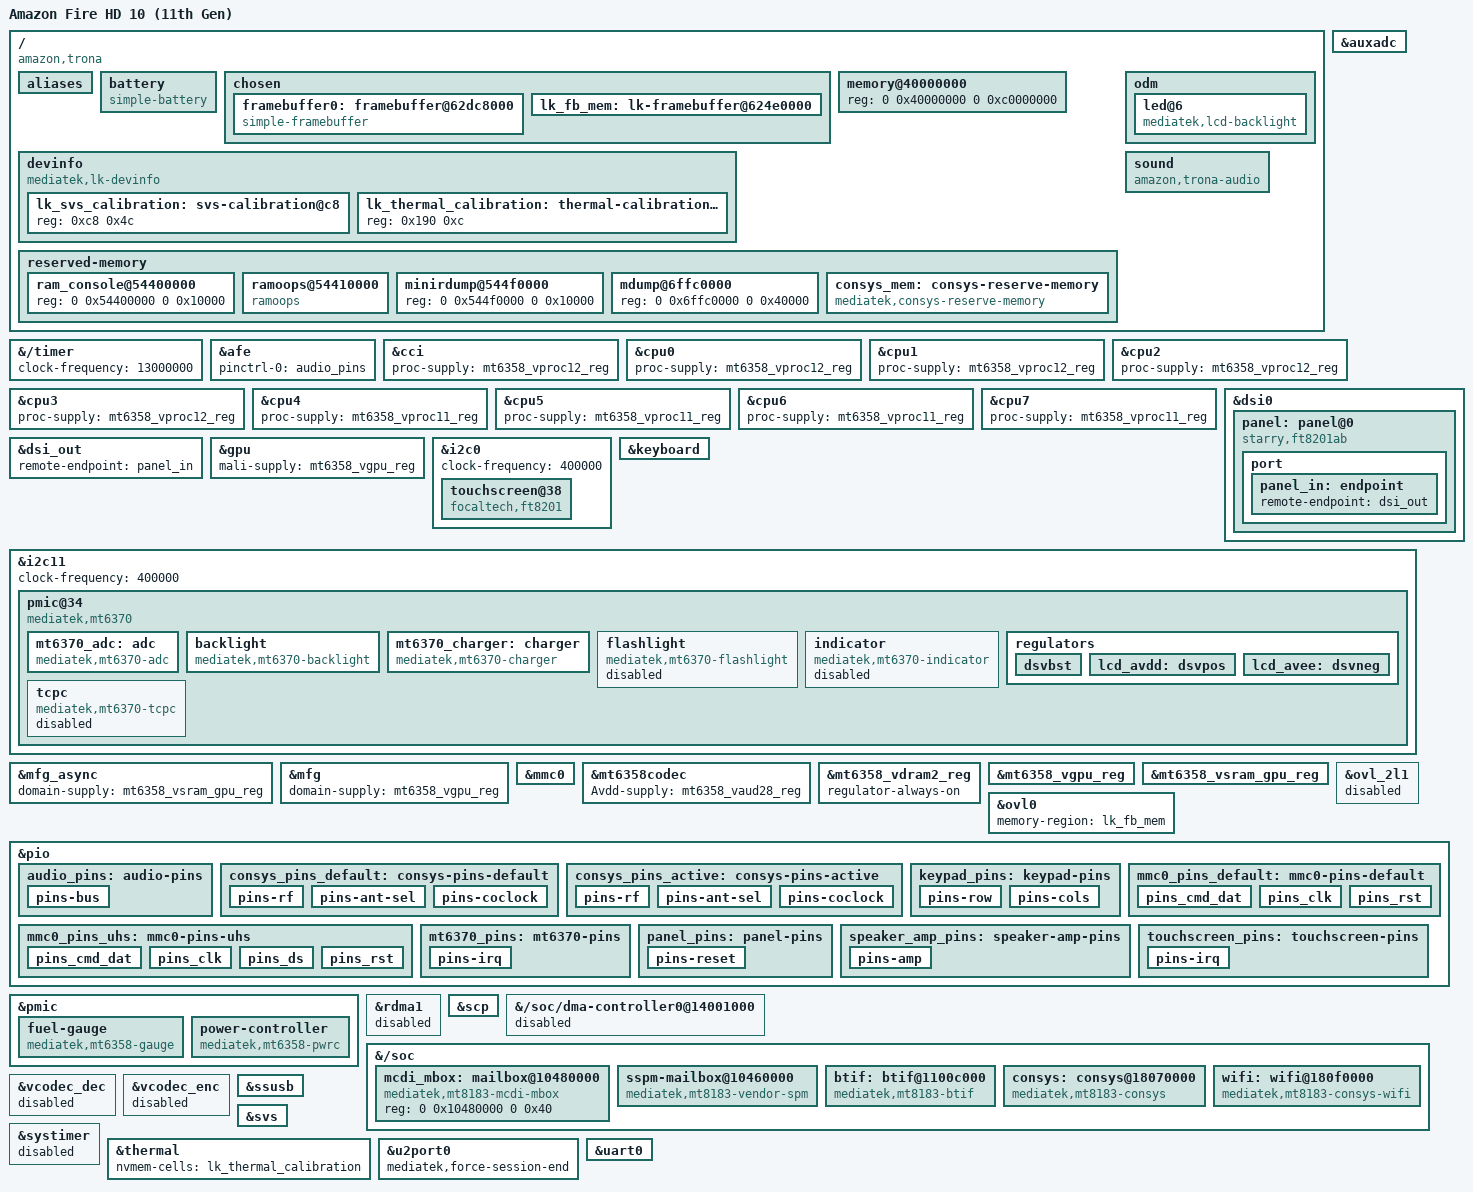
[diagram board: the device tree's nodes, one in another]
// SPDX-License-Identifier: (GPL-2.0 OR MIT)
/*
 * Amazon Fire HD 10 (11th Gen, 2021) - "trona"
 *
 * Initial bring-up: SoC, PMIC, eMMC, USB peripheral, GPU, touchscreen,
 * keys, the MT6358 fuel gauge, the MT6370 backlight, and the display: LK's
 * framebuffer as a simple-framebuffer until mediatek-drm takes the FT8201AB
 * DSI panel over. The rest of the MT6370 (charger/Type-C) and audio are
 * not described yet. WiFi is the SoC's own connectivity subsystem (CONSYS)
 * with an MT6631 RF chip, driven by MediaTek's vendor stack.
 */

/dts-v1/;

#include "mt8183.dtsi"
#include "mt6358.dtsi"
#include <dt-bindings/gpio/gpio.h>
#include <dt-bindings/iio/adc/mediatek,mt6358-auxadc.h>
#include <dt-bindings/iio/adc/mediatek,mt6370_adc.h>

/ {
	model = "Amazon Fire HD 10 (11th Gen)";
	chassis-type = "tablet";
	compatible = "amazon,trona", "mediatek,mt8183";

	/*
	 * Amazon's LK maps the board ID to a hardware revision and only
	 * accepts an appended DTB whose root "version" matches it; otherwise
	 * it boots the kernel with no device tree at all. This unit (and the
	 * vendor DT it shipped with) is "dvt".
	 */
	version = "dvt";

	aliases {
		mmc0 = &mmc0;
		serial0 = &uart0;
	};

	/*
	 * The "NVT/ATL" cell of the vendor gauge's first profile (battery ID
	 * 0: the ID resistor on AUXADC channel 4 reads below 1100 mV). The OCV
	 * table is the vendor's 25 C profile with GM3.0's 6500 mAh Qmax as
	 * 100 percent, so 0 is at 3.655 V and leaves ~300 mAh before the
	 * vendor's 3.4 V shutdown voltage. The internal resistance is what the
	 * gauge sees between the cell and BATSNS: ~158 mV drop at 1.18 A.
	 */
	battery: battery {
		compatible = "simple-battery";
		device-chemistry = "lithium-ion-polymer";
		charge-full-design-microamp-hours = <6500000>;
		voltage-min-design-microvolt = <3400000>;
		voltage-max-design-microvolt = <4400000>;
		constant-charge-voltage-max-microvolt = <4400000>;
		/*
		 * The vendor charges at 3 A, but also lowers voltage and
		 * current by battery temperature, which isn't done here.
		 */
		constant-charge-current-max-microamp = <2000000>;
		charge-term-current-microamp = <350000>;
		factory-internal-resistance-micro-ohms = <130000>;
		ocv-capacity-celsius = <25>;
		ocv-capacity-table-0 = <4384000 100>, <4368000 99>, <4354000 98>, <4342000 97>,
					<4329000 96>, <4317000 95>, <4305000 94>, <4294000 93>,
					<4283000 92>, <4272000 91>, <4260000 90>, <4249000 89>,
					<4238000 88>, <4226000 87>, <4215000 86>, <4204000 85>,
					<4193000 84>, <4182000 83>, <4171000 82>, <4160000 81>,
					<4149000 80>, <4138000 79>, <4128000 78>, <4117000 77>,
					<4107000 76>, <4097000 75>, <4087000 74>, <4078000 73>,
					<4069000 72>, <4060000 71>, <4050000 70>, <4040000 69>,
					<4029000 68>, <4019000 67>, <4010000 66>, <4001000 65>,
					<3992000 64>, <3983000 63>, <3974000 62>, <3967000 61>,
					<3960000 60>, <3952000 59>, <3944000 58>, <3936000 57>,
					<3927000 56>, <3916000 55>, <3905000 54>, <3893000 53>,
					<3883000 52>, <3874000 51>, <3867000 50>, <3861000 49>,
					<3855000 48>, <3850000 47>, <3845000 46>, <3841000 45>,
					<3837000 44>, <3833000 43>, <3829000 42>, <3825000 41>,
					<3821000 40>, <3817000 39>, <3814000 38>, <3810000 37>,
					<3807000 36>, <3805000 35>, <3801000 34>, <3798000 33>,
					<3796000 32>, <3793000 31>, <3790000 30>, <3788000 29>,
					<3786000 28>, <3783000 27>, <3781000 26>, <3777000 25>,
					<3774000 24>, <3769000 23>, <3765000 22>, <3762000 21>,
					<3758000 20>, <3754000 19>, <3750000 18>, <3747000 17>,
					<3744000 16>, <3741000 15>, <3737000 14>, <3731000 13>,
					<3725000 12>, <3720000 11>, <3714000 10>, <3708000 9>,
					<3700000 8>, <3694000 7>, <3692000 6>, <3691000 5>,
					<3690000 4>, <3689000 3>, <3686000 2>, <3679000 1>,
					<3655000 0>;
	};

	chosen {
		#address-cells = <2>;
		#size-cells = <2>;
		ranges;

		/*
		 * LK's bootargs_init() asserts that /chosen/bootargs exists
		 * (and panics otherwise); it uses it as the start of the
		 * command line and appends its own and the boot.img's.
		 */
		bootargs = "console=tty0";
		stdout-path = "serial0:921600n8";

		/*
		 * Keep the kernel off LK's framebuffer carve-out
		 * (0x624e0000-0x64400000). It can't be a no-map node under
		 * /reserved-memory: LK's reserved_memory_conflict_check() spins
		 * forever on any node overlapping its own reservations, and the
		 * "mblock-6-framebuffer" node LK adds itself is mapped. Leaving
		 * it out of System RAM lets simpledrm ioremap it write-combined.
		 */
		linux,usable-memory-range = <0 0x40000000 0 0x224e0000>,
					    <0 0x64400000 0 0x9bc00000>;

		/*
		 * LK initialises the FT8201 panel and hands over with two
		 * full-screen opaque OVL0 layers enabled: layer 0 at the
		 * "atag,videolfb" fb_base (0x624e0000, 1216-pixel pitch) and,
		 * on top of it, layer 3 at 0x62dc8000 with its logo screen.
		 * Only layer 3 is visible, so that is the buffer to draw into.
		 * 1200x1920 portrait, eBGRA8888 in MTK terms.
		 *
		 * The clocks and power domain keep the display path from being
		 * gated as unused during late init if mediatek-drm hasn't taken
		 * over by then. That includes the MIPI TX PHY's 26 MHz reference
		 * (losing it garbles, then blanks, the panel) and the mmsys
		 * 26 MHz clocks LK keeps running.
		 */
		framebuffer0: framebuffer@62dc8000 {
			compatible = "simple-framebuffer";
			reg = <0 0x62dc8000 0 (1200 * 1920 * 4)>;
			width = <1200>;
			height = <1920>;
			stride = <(1200 * 4)>;
			format = "a8r8g8b8";
			power-domains = <&spm MT8183_POWER_DOMAIN_DISP>;
			clocks = <&mmsys CLK_MM_SMI_COMMON>,
				 <&mmsys CLK_MM_SMI_LARB0>,
				 <&mmsys CLK_MM_GALS_COMM0>,
				 <&mmsys CLK_MM_GALS_COMM1>,
				 <&mmsys CLK_MM_DISP_OVL0>,
				 <&mmsys CLK_MM_DISP_OVL0_2L>,
				 <&mmsys CLK_MM_DISP_RDMA0>,
				 <&mmsys CLK_MM_DISP_COLOR0>,
				 <&mmsys CLK_MM_DISP_CCORR0>,
				 <&mmsys CLK_MM_DISP_AAL0>,
				 <&mmsys CLK_MM_DISP_GAMMA0>,
				 <&mmsys CLK_MM_DISP_DITHER0>,
				 <&mmsys CLK_MM_DSI0_MM>,
				 <&mmsys CLK_MM_DSI0_IF>,
				 <&topckgen CLK_TOP_MUX_DISP_PWM>,
				 <&infracfg CLK_INFRA_DISP_PWM>,
				 <&apmixedsys CLK_APMIXED_MIPID0_26M>,
				 <&apmixedsys CLK_APMIXED_MMSYS_26M>,
				 <&mmsys CLK_MM_26M>;
		};

		/*
		 * LK's whole framebuffer carve-out, identity-mapped in the M4U
		 * for OVL0 (memory-region there). OVL0 keeps scanning out LK's
		 * layers by physical address until mediatek-drm reprograms it,
		 * and the M4U takes over its larb port as soon as the display
		 * components probe. Not under /reserved-memory, see above.
		 */
		lk_fb_mem: lk-framebuffer@624e0000 {
			reg = <0 0x624e0000 0 0x1f20000>;
			iommu-addresses = <&ovl0 0 0x624e0000 0 0x1f20000>;
		};
	};

	/*
	 * The preloader's efuse copy, which LK passes in /chosen. The efuse
	 * block itself reads back as zeros from Linux, so calibration data
	 * has to come from here. Cells are by devinfo index (offset 4 * n).
	 */
	devinfo {
		compatible = "mediatek,lk-devinfo";
		#address-cells = <1>;
		#size-cells = <1>;

		/* devinfo[50..68]: the SVS words at efuse 0x580..0x5c8 */
		lk_svs_calibration: svs-calibration@c8 {
			reg = <0xc8 0x4c>;
		};

		/* devinfo[100..102]: the efuse words at 0x180..0x188 */
		lk_thermal_calibration: thermal-calibration@190 {
			reg = <0x190 0xc>;
		};
	};

	/* LK rewrites this with the real DRAM layout (3 GiB on this SKU). */
	memory@40000000 {
		device_type = "memory";
		reg = <0 0x40000000 0 0xc0000000>;
	};

	/*
	 * Only regions LK does not reserve itself go here. LK adds its own
	 * carve-outs (ATF, TEE, SPM, SSPM, VPU no-map, plus the framebuffer)
	 * as "mblock-N-*" nodes at boot, and its
	 * reserved_memory_conflict_check() hangs in "fatal error keep
	 * while (1)" if any node here overlaps them, exact duplicates
	 * included.
	 */
	reserved-memory {
		#address-cells = <2>;
		#size-cells = <2>;
		ranges;

		ram_console@54400000 {
			reg = <0 0x54400000 0 0x10000>;
		};

		/* Vendor pstore region, reused for ramoops across warm reboots. */
		ramoops@54410000 {
			compatible = "ramoops";
			reg = <0 0x54410000 0 0xe0000>;
			/*
			 * The vendor kernel lays its zones out differently, so
			 * TWRP can't read these back; tools/trona-pl-rescue.py
			 * finds them from the preloader instead.
			 */
			record-size = <0x1000>;
			console-size = <0x40000>;
			/* 32 KiB per CPU for pstore/ftrace hang hunting */
			ftrace-size = <0x40000>;
			flags = <1>; /* RAMOOPS_FLAG_FTRACE_PER_CPU */
			pmsg-size = <0x10000>;
		};

		minirdump@544f0000 {
			reg = <0 0x544f0000 0 0x10000>;
		};

		mdump@6ffc0000 {
			reg = <0 0x6ffc0000 0 0x40000>;
		};

		/*
		 * Memory the CONSYS shares with the kernel: its WiFi firmware
		 * and its logs and dumps. Placed by the kernel like the vendor
		 * DT's, so there is no "reg" for LK to compare with its own
		 * reservations. The CONSYS reaches it through a remap register
		 * that takes the address in 2 MiB units and can't point above
		 * 0xc0000000.
		 */
		consys_mem: consys-reserve-memory {
			compatible = "mediatek,consys-reserve-memory";
			size = <0 0x200000>;
			alignment = <0 0x200000>;
			alloc-ranges = <0 0x40000000 0 0x80000000>;
			no-map;
		};
	};

	/*
	 * Not used by Linux. Amazon's LK only turns the MT6370 backlight on
	 * (at the IDME bl_level) when it finds this vendor node at
	 * /odm/led@6; without it the panel is initialised but stays dark.
	 */
	odm {
		#address-cells = <1>;
		#size-cells = <0>;

		led@6 {
			compatible = "mediatek,lcd-backlight";
			reg = <6>;
			led_mode = <3>;
			data = <1>;
			pwm_config = <0 1 0 0 0>;
		};
	};

	/*
	 * Trona has no I2S/I2C smart amplifier and no I2C jack-detect chip:
	 * the speaker is driven from MT6358's own analog headphone/line-out
	 * stage into a discrete Class-D amplifier controlled purely by two
	 * GPIOs (enable + a static gain-mode select), and the microphone is
	 * MT6358's own analog AIN0/AIN2 input pair. "amazon,trona-audio" is
	 * this board's machine driver, not an upstream binding (see
	 * sound/soc/mediatek/mt8183/mt8183-mt6358-trona.c). GPIO numbers,
	 * polarity and the amplifier's enable timing come from a
	 * third-party mainline port of this exact tablet
	 * (Cesarus85/omarchy-amazon-fire-hd10), itself sourced from the
	 * shipped Amazon Trona device tree and mtk-auddrv-gpio.c; both
	 * GPIOs read back unclaimed on the live device.
	 */
	sound: sound {
		compatible = "amazon,trona-audio";
		mediatek,platform = <&afe>;
		pinctrl-names = "default";
		pinctrl-0 = <&speaker_amp_pins>;
		speaker-enable-gpios = <&pio 151 GPIO_ACTIVE_HIGH>;
		speaker-gain-gpios = <&pio 150 GPIO_ACTIVE_HIGH>;
	};
};

/*
 * The vendor DT hardcodes the 13 MHz system counter frequency; don't rely on
 * the vendor ATF having programmed CNTFRQ_EL0.
 */
&{/timer} {
	clock-frequency = <13000000>;
};

/*
 * MTKAIF 3.0: the digital link between the AFE and MT6358's own ADC/DAC.
 * Same eight pins as every other MT8183 board (e.g. mt8183-kukui.dtsi's
 * aud_pins_default); &afe and &mt6358codec themselves need no status
 * override, they default to "okay" via mt8183.dtsi/mt6358.dtsi.
 */
&afe {
	pinctrl-names = "default";
	pinctrl-0 = <&audio_pins>;
};

/*
 * Channel 4 reads the battery cell ID resistor (the vendor gauge picks its
 * battery profile from it).
 */
&auxadc {
	status = "okay";
};

&cci {
	proc-supply = <&mt6358_vproc12_reg>;
};

&cpu0 {
	proc-supply = <&mt6358_vproc12_reg>;
};

&cpu1 {
	proc-supply = <&mt6358_vproc12_reg>;
};

&cpu2 {
	proc-supply = <&mt6358_vproc12_reg>;
};

&cpu3 {
	proc-supply = <&mt6358_vproc12_reg>;
};

&cpu4 {
	proc-supply = <&mt6358_vproc11_reg>;
};

&cpu5 {
	proc-supply = <&mt6358_vproc11_reg>;
};

&cpu6 {
	proc-supply = <&mt6358_vproc11_reg>;
};

&cpu7 {
	proc-supply = <&mt6358_vproc11_reg>;
};

&dsi0 {
	#address-cells = <1>;
	#size-cells = <0>;
	status = "okay";

	panel: panel@0 {
		compatible = "starry,ft8201ab";
		reg = <0>;
		pinctrl-names = "default";
		pinctrl-0 = <&panel_pins>;
		reset-gpios = <&pio 45 GPIO_ACTIVE_LOW>;
		touch-reset-gpios = <&pio 2 GPIO_ACTIVE_LOW>;
		vddi-supply = <&mt6358_vrf18_reg>;
		avdd-supply = <&lcd_avdd>;
		avee-supply = <&lcd_avee>;
		backlight = <&backlight>;
		/* Landscape device: the panel's left edge is at the camera */
		rotation = <270>;

		port {
			panel_in: endpoint {
				remote-endpoint = <&dsi_out>;
			};
		};
	};
};

&dsi_out {
	remote-endpoint = <&panel_in>;
};

&gpu {
	mali-supply = <&mt6358_vgpu_reg>;
};

&i2c0 {
	clock-frequency = <400000>;
	status = "okay";

	/*
	 * Touch half of the FT8201AB in-cell panel controller. Its reset
	 * (GPIO2) is sequenced together with the panel's, so it belongs to
	 * the panel; touch only works while the panel is powered.
	 */
	touchscreen@38 {
		compatible = "focaltech,ft8201";
		reg = <0x38>;
		interrupts-extended = <&pio 1 IRQ_TYPE_EDGE_FALLING>;
		pinctrl-names = "default";
		pinctrl-0 = <&touchscreen_pins>;
		vcc-supply = <&mt6358_vldo28_reg>;
		iovcc-supply = <&mt6358_vrf18_reg>;
		touchscreen-size-x = <1200>;
		touchscreen-size-y = <1920>;
	};
};

/*
 * Volume keys, wired as "direct keys": KPCOL0/KPCOL1 against row 0, which
 * is a GPIO held low rather than KPROW0 (as LK sets it up). The MT6358
 * power key is reported by mtk-pmic-keys.
 */
&keyboard {
	pinctrl-names = "default";
	pinctrl-0 = <&keypad_pins>;
	linux,keymap = <MATRIX_KEY(0, 0, KEY_VOLUMEDOWN)
			MATRIX_KEY(0, 1, KEY_VOLUMEUP)>;
	keypad,num-rows = <1>;
	keypad,num-columns = <2>;
	debounce-delay-ms = <32>;
	mediatek,keys-per-group = <1>;
	status = "okay";
};

/*
 * MT6370 sub-PMIC ("i2c5" in Amazon's tree). Only the backlight is driven
 * for now: Amazon's LK leaves the BLED in PWM-dimming mode with nothing
 * feeding the PWM input, so the panel stays dark. The driver switches it
 * to I2C dimming. Settings mirror the vendor bled node (4 channels,
 * OVP 29 V, OCP 1.5 A, brightness capped at 1370). The display bias
 * rails (AVDD/AVEE) for the panel come from this chip too, at the
 * vendor's +-6.0 V off a 6.2 V boost.
 */
&i2c11 {
	clock-frequency = <400000>;
	status = "okay";

	pmic@34 {
		compatible = "mediatek,mt6370";
		reg = <0x34>;
		interrupts-extended = <&pio 10 IRQ_TYPE_LEVEL_LOW>;
		pinctrl-names = "default";
		pinctrl-0 = <&mt6370_pins>;
		interrupt-controller;
		#interrupt-cells = <1>;
		wakeup-source;

		mt6370_adc: adc {
			compatible = "mediatek,mt6370-adc";
			#io-channel-cells = <1>;
		};

		backlight: backlight {
			compatible = "mediatek,mt6370-backlight";
			mediatek,bled-channel-use = /bits/ 8 <15>;
			mediatek,bled-ovp-microvolt = <29000000>;
			mediatek,bled-ocp-microamp = <1500000>;
			max-brightness = <1370>;
			default-brightness = <512>;
		};

		/* Not brought up yet; keep their drivers off the hardware. */
		/*
		 * Charge settings come from the battery node; the input
		 * current limit follows the BC1.2 result. The USB PHY is
		 * switched off D+/D- while BC1.2 runs.
		 */
		mt6370_charger: charger {
			compatible = "mediatek,mt6370-charger";
			interrupts = <68>, <48>, <6>;
			interrupt-names = "uvp_d_evt", "attach_i", "mivr";
			phys = <&u2port0 PHY_TYPE_USB2>;
			phy-names = "usb";
			io-channels = <&mt6370_adc MT6370_CHAN_VBUSDIV5>,
				      <&mt6370_adc MT6370_CHAN_VBUSDIV2>,
				      <&mt6370_adc MT6370_CHAN_VSYS>,
				      <&mt6370_adc MT6370_CHAN_VBAT>,
				      <&mt6370_adc MT6370_CHAN_TS_BAT>,
				      <&mt6370_adc MT6370_CHAN_IBUS>,
				      <&mt6370_adc MT6370_CHAN_IBAT>,
				      <&mt6370_adc MT6370_CHAN_CHG_VDDP>,
				      <&mt6370_adc MT6370_CHAN_TEMP_JC>;
			io-channel-names = "vbusdiv5", "vbusdiv2", "vsys",
					   "vbat", "ts_bat", "ibus", "ibat",
					   "chg_vddp", "temp_jc";
			monitored-battery = <&battery>;
		};

		flashlight {
			compatible = "mediatek,mt6370-flashlight";
			status = "disabled";
		};

		indicator {
			compatible = "mediatek,mt6370-indicator";
			status = "disabled";
		};

		regulators {
			dsvbst {
				regulator-name = "lcd_bias_boost";
				regulator-min-microvolt = <6200000>;
				regulator-max-microvolt = <6200000>;
			};

			lcd_avdd: dsvpos {
				regulator-name = "lcd_avdd";
				regulator-min-microvolt = <6000000>;
				regulator-max-microvolt = <6000000>;
			};

			lcd_avee: dsvneg {
				regulator-name = "lcd_avee";
				regulator-min-microvolt = <6000000>;
				regulator-max-microvolt = <6000000>;
			};
		};

		tcpc {
			compatible = "mediatek,mt6370-tcpc";
			status = "disabled";
		};
	};
};

&mfg_async {
	domain-supply = <&mt6358_vsram_gpu_reg>;
};

&mfg {
	domain-supply = <&mt6358_vgpu_reg>;
};

&mmc0 {
	pinctrl-names = "default", "state_uhs";
	pinctrl-0 = <&mmc0_pins_default>;
	pinctrl-1 = <&mmc0_pins_uhs>;
	bus-width = <8>;
	max-frequency = <200000000>;
	cap-mmc-highspeed;
	/* HS400 needs board-specific ds-delay tuning; HS200 until verified. */
	mmc-hs200-1_8v;
	cap-mmc-hw-reset;
	no-sdio;
	no-sd;
	non-removable;
	vmmc-supply = <&mt6358_vemc_reg>;
	vqmmc-supply = <&mt6358_vio18_reg>;
	assigned-clocks = <&topckgen CLK_TOP_MUX_MSDC50_0>;
	assigned-clock-parents = <&topckgen CLK_TOP_MSDCPLL_CK>;
	status = "okay";
};

/* AVDD for the codec's own analog output stage (the speaker/HP path). */
&mt6358codec {
	Avdd-supply = <&mt6358_vaud28_reg>;
};

/*
 * LPDDR4X VDDQ (as on kukui). Unclaimed, it was switched off by the
 * regulator late cleanup 30 s after boot, and the system died with it.
 */
&mt6358_vdram2_reg {
	regulator-always-on;
};

&mt6358_vgpu_reg {
	regulator-min-microvolt = <625000>;
	regulator-max-microvolt = <900000>;

	regulator-coupled-with = <&mt6358_vsram_gpu_reg>;
	regulator-coupled-max-spread = <100000>;
};

&mt6358_vsram_gpu_reg {
	regulator-min-microvolt = <850000>;
	regulator-max-microvolt = <1000000>;

	regulator-coupled-with = <&mt6358_vgpu_reg>;
	regulator-coupled-max-spread = <100000>;
};

/*
 * When the display components probe they attach to the IOMMU, which turns
 * on translation for the larb0 display ports while OVL0 is still scanning
 * out LK's framebuffer by physical address. Without this identity mapping
 * that means endless translation faults and a dead picture under simpledrm.
 */
&ovl0 {
	memory-region = <&lk_fb_mem>;
};

/* External display path (DPI); nothing is connected to it. */
&ovl_2l1 {
	status = "disabled";
};

&pio {
	/*
	 * MTKAIF 3.0 bus between the AFE and MT6358's own ADC/DAC, same
	 * pins/function/drive-strength as every other MT8183 board.
	 */
	audio_pins: audio-pins {
		pins-bus {
			pinmux = <PINMUX_GPIO136__FUNC_AUD_CLK_MOSI>,
				 <PINMUX_GPIO137__FUNC_AUD_SYNC_MOSI>,
				 <PINMUX_GPIO138__FUNC_AUD_DAT_MOSI0>,
				 <PINMUX_GPIO139__FUNC_AUD_DAT_MOSI1>,
				 <PINMUX_GPIO140__FUNC_AUD_CLK_MISO>,
				 <PINMUX_GPIO141__FUNC_AUD_SYNC_MISO>,
				 <PINMUX_GPIO142__FUNC_AUD_DAT_MISO0>,
				 <PINMUX_GPIO143__FUNC_AUD_DAT_MISO1>;
			drive-strength = <MTK_DRIVE_4mA>;
			bias-disable;
		};
	};

	/*
	 * GPIO113..121 are the CONSYS's lines to the MT6631 RF chip; they are
	 * only handed to it while it is powered. GPIO156 selects the WiFi
	 * antenna. GPIO7 is a board strap for where the 26 MHz reference comes
	 * from; its pull is left as LK set it.
	 */
	consys_pins_default: consys-pins-default {
		pins-rf {
			pinmux = <PINMUX_GPIO113__FUNC_GPIO113>,
				 <PINMUX_GPIO114__FUNC_GPIO114>,
				 <PINMUX_GPIO115__FUNC_GPIO115>,
				 <PINMUX_GPIO116__FUNC_GPIO116>,
				 <PINMUX_GPIO117__FUNC_GPIO117>,
				 <PINMUX_GPIO118__FUNC_GPIO118>,
				 <PINMUX_GPIO119__FUNC_GPIO119>,
				 <PINMUX_GPIO120__FUNC_GPIO120>,
				 <PINMUX_GPIO121__FUNC_GPIO121>;
		};

		pins-ant-sel {
			pinmux = <PINMUX_GPIO156__FUNC_GPIO156>;
			bias-disable;
		};

		pins-coclock {
			pinmux = <PINMUX_GPIO7__FUNC_GPIO7>;
			input-enable;
		};
	};

	consys_pins_active: consys-pins-active {
		pins-rf {
			pinmux = <PINMUX_GPIO113__FUNC_CONN_TOP_CLK>,
				 <PINMUX_GPIO114__FUNC_CONN_TOP_DATA>,
				 <PINMUX_GPIO115__FUNC_CONN_BT_CLK>,
				 <PINMUX_GPIO116__FUNC_CONN_BT_DATA>,
				 <PINMUX_GPIO117__FUNC_CONN_WF_HB0>,
				 <PINMUX_GPIO118__FUNC_CONN_WF_HB1>,
				 <PINMUX_GPIO119__FUNC_CONN_WF_HB2>,
				 <PINMUX_GPIO120__FUNC_CONN_WB_PTA>,
				 <PINMUX_GPIO121__FUNC_CONN_HRST_B>;
		};

		pins-ant-sel {
			pinmux = <PINMUX_GPIO156__FUNC_GPIO156>;
			bias-disable;
		};

		pins-coclock {
			pinmux = <PINMUX_GPIO7__FUNC_GPIO7>;
			input-enable;
		};
	};

	keypad_pins: keypad-pins {
		pins-row {
			pinmux = <PINMUX_GPIO92__FUNC_GPIO92>;
			output-low;
		};

		pins-cols {
			pinmux = <PINMUX_GPIO93__FUNC_KPCOL0>,
				 <PINMUX_GPIO94__FUNC_KPCOL1>;
			input-enable;
			bias-pull-up = <MTK_PUPD_SET_R1R0_01>;
		};
	};

	mmc0_pins_default: mmc0-pins-default {
		pins_cmd_dat {
			pinmux = <PINMUX_GPIO123__FUNC_MSDC0_DAT0>,
				 <PINMUX_GPIO128__FUNC_MSDC0_DAT1>,
				 <PINMUX_GPIO125__FUNC_MSDC0_DAT2>,
				 <PINMUX_GPIO132__FUNC_MSDC0_DAT3>,
				 <PINMUX_GPIO126__FUNC_MSDC0_DAT4>,
				 <PINMUX_GPIO129__FUNC_MSDC0_DAT5>,
				 <PINMUX_GPIO127__FUNC_MSDC0_DAT6>,
				 <PINMUX_GPIO130__FUNC_MSDC0_DAT7>,
				 <PINMUX_GPIO122__FUNC_MSDC0_CMD>;
			input-enable;
			drive-strength = <MTK_DRIVE_14mA>;
			mediatek,pull-up-adv = <01>;
		};

		pins_clk {
			pinmux = <PINMUX_GPIO124__FUNC_MSDC0_CLK>;
			drive-strength = <MTK_DRIVE_14mA>;
			mediatek,pull-down-adv = <2>;
		};

		pins_rst {
			pinmux = <PINMUX_GPIO133__FUNC_MSDC0_RSTB>;
			drive-strength = <MTK_DRIVE_14mA>;
			mediatek,pull-down-adv = <01>;
		};
	};

	mmc0_pins_uhs: mmc0-pins-uhs {
		pins_cmd_dat {
			pinmux = <PINMUX_GPIO123__FUNC_MSDC0_DAT0>,
				 <PINMUX_GPIO128__FUNC_MSDC0_DAT1>,
				 <PINMUX_GPIO125__FUNC_MSDC0_DAT2>,
				 <PINMUX_GPIO132__FUNC_MSDC0_DAT3>,
				 <PINMUX_GPIO126__FUNC_MSDC0_DAT4>,
				 <PINMUX_GPIO129__FUNC_MSDC0_DAT5>,
				 <PINMUX_GPIO127__FUNC_MSDC0_DAT6>,
				 <PINMUX_GPIO130__FUNC_MSDC0_DAT7>,
				 <PINMUX_GPIO122__FUNC_MSDC0_CMD>;
			input-enable;
			drive-strength = <MTK_DRIVE_14mA>;
			mediatek,pull-up-adv = <01>;
		};

		pins_clk {
			pinmux = <PINMUX_GPIO124__FUNC_MSDC0_CLK>;
			drive-strength = <MTK_DRIVE_14mA>;
			mediatek,pull-down-adv = <2>;
		};

		pins_ds {
			pinmux = <PINMUX_GPIO131__FUNC_MSDC0_DSL>;
			drive-strength = <MTK_DRIVE_14mA>;
			mediatek,pull-down-adv = <2>;
		};

		pins_rst {
			pinmux = <PINMUX_GPIO133__FUNC_MSDC0_RSTB>;
			drive-strength = <MTK_DRIVE_14mA>;
			mediatek,pull-up-adv = <01>;
		};
	};

	/*
	 * IRQB is open-drain. The board's GPIO table wants the SoC pull-up
	 * here, but the pin arrives pulled down, which holds the level IRQ
	 * asserted until the core shuts it off as spurious.
	 */
	mt6370_pins: mt6370-pins {
		pins-irq {
			pinmux = <PINMUX_GPIO10__FUNC_GPIO10>;
			input-enable;
			bias-pull-up;
		};
	};

	/* LK leaves both resets deasserted (high) with the panel running. */
	panel_pins: panel-pins {
		pins-reset {
			pinmux = <PINMUX_GPIO45__FUNC_GPIO45>,
				 <PINMUX_GPIO2__FUNC_GPIO2>;
			output-high;
		};
	};

	/*
	 * Discrete Class-D speaker amplifier downstream of MT6358's analog
	 * headphone output: GPIO151 is its enable, GPIO150 selects its
	 * (fixed) gain mode. Both come up low (amplifier off) until the
	 * machine driver's DAPM speaker widget turns them on.
	 */
	speaker_amp_pins: speaker-amp-pins {
		pins-amp {
			pinmux = <PINMUX_GPIO150__FUNC_GPIO150>,
				 <PINMUX_GPIO151__FUNC_GPIO151>;
			output-low;
		};
	};

	touchscreen_pins: touchscreen-pins {
		pins-irq {
			pinmux = <PINMUX_GPIO1__FUNC_GPIO1>;
			input-enable;
			bias-disable;
		};
	};
};

&pmic {
	interrupts-extended = <&pio 182 IRQ_TYPE_LEVEL_HIGH>;

	fuel-gauge {
		compatible = "mediatek,mt6358-gauge";
		io-channels = <&pmic_adc MT6358_AUXADC_BATADC>;
		io-channel-names = "vbat";
		monitored-battery = <&battery>;
		power-supplies = <&mt6370_charger>;
	};

	/*
	 * The vendor TF-A doesn't power the PMIC off for PSCI SYSTEM_OFF; the
	 * kernel has to. With a cable in, the PMIC powers right back on.
	 */
	power-controller {
		compatible = "mediatek,mt6358-pwrc";
	};
};

&rdma1 {
	status = "disabled";
};

/*
 * The SCP stays disabled (as in mt8183.dtsi) until it has a carve-out and
 * firmware. The video codecs and MDP3 can't work without it, and their
 * drivers WARN when they can't find it, so keep them off too.
 */
&scp {
	/delete-property/ memory-region;
};

&{/soc/dma-controller0@14001000} {
	status = "disabled";
};

/*
 * SSPM mailbox 3: the MCDI controller that powers CPUs down for PSCI idle
 * states. The vendor TF-A needs the kernel to set it up, or a CPU entering
 * a power-down idle state hangs the system.
 */
&{/soc} {
	mcdi_mbox: mailbox@10480000 {
		compatible = "mediatek,mt8183-mcdi-mbox";
		reg = <0 0x10480000 0 0x40>;
	};

	/*
	 * System suspend through the vendor SPM firmware, which this TF-A
	 * leaves to the kernel to set up. SSPM mailbox 1 (data, IRQ
	 * registers) carries the SPM suspend IPI.
	 */
	sspm-mailbox@10460000 {
		compatible = "mediatek,mt8183-vendor-spm";
		/* SSPM mailbox 1 data and IRQ registers, the SPM itself */
		reg = <0 0x10460000 0 0x100>, <0 0x10461000 0 0x8>,
		      <0 0x10006000 0 0x1000>;
		/* The SPM's interrupt; it wakes CPU0, so it stays unmasked */
		interrupts = <GIC_SPI 187 IRQ_TYPE_LEVEL_LOW>;
		/* LPDDR4X, 2 channels, 3200 MT/s: SPMFW_LP4X_2CH_3200 */
		mediatek,spm-firmware-index = <1>;
		/*
		 * MediaTek's: DIS_VCORE_DVS | DIS_VCORE_DFS | DIS_ATF_ABORT |
		 * SUSPEND_OPTION. Infra is powered down too; the USB and
		 * thermal drivers set their (reset) controllers up again.
		 */
		mediatek,pcm-flags = <0x00080098>;
		/* BIG_BUCK_OFF_ENABLE | BIG_BUCK_ON_ENABLE: vproc11 stays on */
		mediatek,pcm-flags1 = <0x300>;
		/* PCM timer wake-up: 36 h (32768 Hz ticks), MediaTek's limit */
		mediatek,timer-val = <0xfd200000>;
		/* Bring-up: breadcrumbs in the unused vendor ram_console area */
		mediatek,breadcrumbs = <0x54408000>;
	};

	/*
	 * The connectivity subsystem (CONSYS): a microcontroller with WiFi and
	 * Bluetooth MACs in its own power domain, and an MT6631 RF chip. It is
	 * driven by MediaTek's vendor stack, which finds its resources by
	 * position, so the order of the reg and interrupt entries matters.
	 *
	 * BTIF is the UART the kernel talks to the microcontroller over, with
	 * two APDMA channels of its own past the ones the "apdma" node has.
	 */
	btif: btif@1100c000 {
		compatible = "mediatek,mt8183-btif";
		reg = <0 0x1100c000 0 0x1000>,	/* BTIF */
		      <0 0x11000a80 0 0x80>,	/* APDMA, BTIF TX */
		      <0 0x11000b00 0 0x80>;	/* APDMA, BTIF RX */
		interrupts = <GIC_SPI 114 IRQ_TYPE_LEVEL_LOW>,
			     <GIC_SPI 139 IRQ_TYPE_LEVEL_LOW>,
			     <GIC_SPI 140 IRQ_TYPE_LEVEL_LOW>;
		clocks = <&infracfg CLK_INFRA_BTIF>,
			 <&infracfg CLK_INFRA_AP_DMA>;
		clock-names = "btifc", "apdmac";
	};

	consys: consys@18070000 {
		compatible = "mediatek,mt8183-consys";
		reg = <0 0x18070000 0 0x1000>,	/* CONN_MCU_CONFIG */
		      <0 0x180b6000 0 0x100>;	/* CONN AFE */
		interrupts = <GIC_SPI 289 IRQ_TYPE_LEVEL_LOW>,	/* BGF wakeup */
			     <GIC_SPI 291 IRQ_TYPE_LEVEL_LOW>;	/* watchdog */
		power-domains = <&spm MT8183_POWER_DOMAIN_CONN>;
		resets = <&watchdog MT8183_TOPRGU_CONN_MCU_SW_RST>;
		reset-names = "mcu";
		/* The CONSYS's own channel to the PMIC, for its 26 MHz request */
		clocks = <&infracfg CLK_INFRA_PMIC_CONN>;
		clock-names = "pmic-conn";
		memory-region = <&consys_mem>;
		mediatek,infracfg = <&infracfg>;
		mediatek,pmic = <&pmic>;
		vcn18-supply = <&mt6358_vcn18_reg>;
		vcn28-supply = <&mt6358_vcn28_reg>;
		vcn33-supply = <&mt6358_vcn33_reg>;
		pinctrl-names = "default", "active";
		pinctrl-0 = <&consys_pins_default>;
		pinctrl-1 = <&consys_pins_active>;
		/*
		 * High: the 26 MHz reference is the PMIC's XO_WCN buffer. Low:
		 * the RF chip has its own TCXO, powered from vcn28.
		 */
		coclock-gpios = <&pio 7 GPIO_ACTIVE_HIGH>;
		/* Asserted (the pin low) selects the auxiliary antenna */
		ant-sel-gpios = <&pio 156 GPIO_ACTIVE_LOW>;
	};

	/*
	 * No power-domains here: the WiFi function is only touched while the
	 * CONSYS driver has the domain on, and a second consumer that doesn't
	 * do runtime PM would hold it on for good.
	 */
	wifi: wifi@180f0000 {
		compatible = "mediatek,mt8183-consys-wifi";
		reg = <0 0x180f0000 0 0x1100>,	/* WiFi host interface */
		      <0 0x10212180 0 0x6c>,	/* CQDMA channel */
		      <0 0x180e0000 0 0x70>;	/* CONN remap config */
		interrupts = <GIC_SPI 290 IRQ_TYPE_LEVEL_LOW>,	/* host interface */
			     <GIC_SPI 118 IRQ_TYPE_LEVEL_LOW>;	/* CQDMA */
		clocks = <&infracfg CLK_INFRA_CQ_DMA>;
		clock-names = "wifi-dma";
		mediatek,infracfg = <&infracfg>;
		/* Chip ID, firmware load address, firmware start address */
		hardware-values = <0x00000788>, <0x000a5800>, <0x000a5800>;
	};
};

&vcodec_dec {
	status = "disabled";
};

&vcodec_enc {
	status = "disabled";
};

/*
 * Peripheral-only until the MT6370 TCPC is described and can drive role
 * switching. USB 2.0 only on this device.
 *
 * VBUS doesn't reach the PHY's comparator (the MT6370 senses it), so the
 * device controller forces VBUS valid itself, and drops that across system
 * suspend so the IP can sleep.
 */
&ssusb {
	dr_mode = "peripheral";
	maximum-speed = "high-speed";
	mediatek,force-vbus;
	/*
	 * No USB3 here: the U3 MAC clock never becomes stable (LK reports
	 * the same), and mtu3 refuses to start while it waits for it.
	 */
	mediatek,u3p-dis-msk = <1>;
	vusb33-supply = <&mt6358_vusb_reg>;
	status = "okay";
};

/* The efuse reads as blank; take the calibration from LK's devinfo copy */
&svs {
	nvmem-cells = <&lk_svs_calibration>, <&lk_thermal_calibration>;
	nvmem-cell-names = "svs-calibration-data", "t-calibration-data";
};

/*
 * The stock kernel only reads this timer's counter; the vendor firmware
 * appears to use the compare channel timer-mediatek drives as the broadcast
 * clockevent. With it enabled the SoC froze a tick or two after the switch
 * to oneshot mode. arm64 falls back to the hrtimer-based broadcast.
 */
&systimer {
	status = "disabled";
};

/*
 * Without the real calibration the sensors read ~20 C at idle and ran
 * into the 115 C critical trip under an all-core load.
 */
&thermal {
	nvmem-cells = <&lk_thermal_calibration>;
};

/*
 * With the PHY's own session signals left alone (or forced valid, as the
 * vendor driver does), the SSUSB IP never enters sleep and system suspend
 * fails with -EBUSY. The device controller forces VBUS instead (above).
 */
&u2port0 {
	mediatek,force-session-end;
};

&uart0 {
	status = "okay";
};
